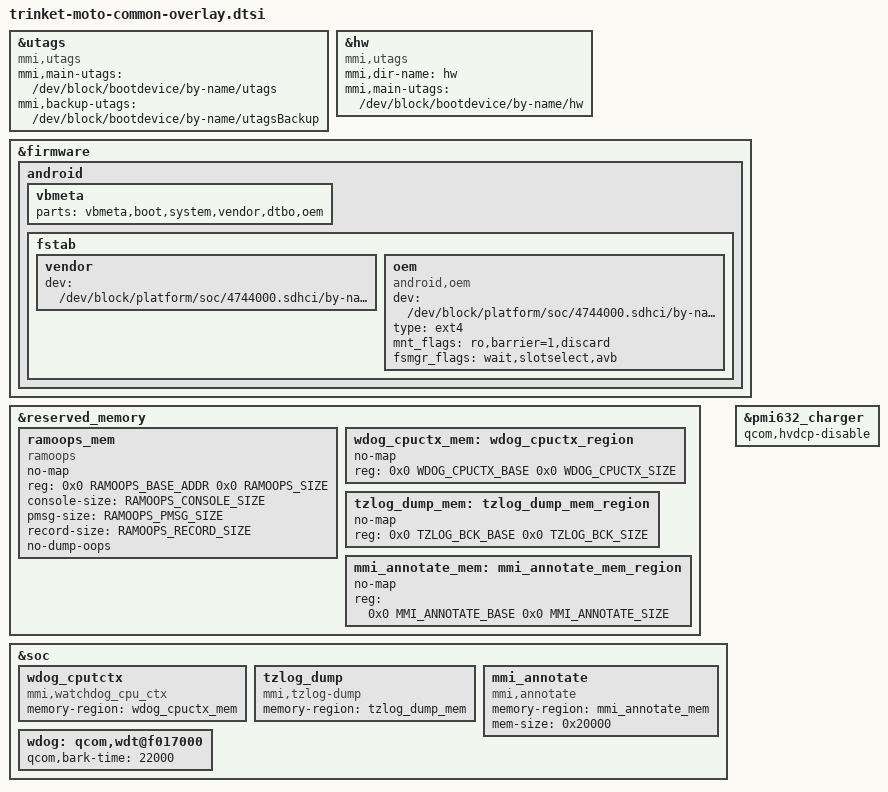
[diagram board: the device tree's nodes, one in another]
/* Copyright (c) 2018, The Linux Foundation. All rights reserved.
 *
 * This program is free software; you can redistribute it and/or modify
 * it under the terms of the GNU General Public License version 2 and
 * only version 2 as published by the Free Software Foundation.
 *
 * This program is distributed in the hope that it will be useful,
 * but WITHOUT ANY WARRANTY; without even the implied warranty of
 * MERCHANTABILITY or FITNESS FOR A PARTICULAR PURPOSE.  See the
 * GNU General Public License for more details.
 */

#include "trinket-qrd.dtsi"
#include <dt-bindings/moto/moto-mem-reserve.h>

&utags {
	compatible = "mmi,utags";
	mmi,main-utags = "/dev/block/bootdevice/by-name/utags";
	mmi,backup-utags = "/dev/block/bootdevice/by-name/utagsBackup";
};

&hw {
	compatible = "mmi,utags";
	mmi,dir-name = "hw";
	mmi,main-utags = "/dev/block/bootdevice/by-name/hw";
};


&firmware {
       android {
               vbmeta {
                       parts = "vbmeta,boot,system,vendor,dtbo,oem";
               };
               fstab {
                       vendor {
                               dev = "/dev/block/platform/soc/4744000.sdhci/by-name/vendor";
                       };
                       oem {
                               compatible = "android,oem";
                               dev = "/dev/block/platform/soc/4744000.sdhci/by-name/oem";
                               type = "ext4";
                               mnt_flags = "ro,barrier=1,discard";
                               fsmgr_flags = "wait,slotselect,avb";
                       };
               };
       };
};

&reserved_memory {
	ramoops_mem {
		compatible = "ramoops";
		no-map;
		reg = <0x0 RAMOOPS_BASE_ADDR 0x0 RAMOOPS_SIZE>;
		console-size = <RAMOOPS_CONSOLE_SIZE>;
		pmsg-size = <RAMOOPS_PMSG_SIZE>;
		record-size = <RAMOOPS_RECORD_SIZE>;
		no-dump-oops;
	};

	wdog_cpuctx_mem: wdog_cpuctx_region {
		no-map;
		reg = <0x0 WDOG_CPUCTX_BASE
				0x0 WDOG_CPUCTX_SIZE>;
	};

	tzlog_dump_mem: tzlog_dump_mem_region {
		no-map;
		reg = <0x0  TZLOG_BCK_BASE
				0x0 TZLOG_BCK_SIZE>;
	};

	mmi_annotate_mem: mmi_annotate_mem_region {
		no-map;
		reg = <0x0  MMI_ANNOTATE_BASE
				0x0 MMI_ANNOTATE_SIZE>;
	};

};

&soc {
	wdog_cputctx {
		compatible = "mmi,watchdog_cpu_ctx";
		memory-region = <&wdog_cpuctx_mem>;
	};

	tzlog_dump {
		compatible = "mmi,tzlog-dump";
		memory-region = <&tzlog_dump_mem>;
	};

	mmi_annotate {
		compatible = "mmi,annotate";
		memory-region = <&mmi_annotate_mem>;
		mem-size = <0x20000>;
	};

	wdog: qcom,wdt@f017000 {
		qcom,bark-time = <22000>;
	};
};

&pmi632_charger {
	qcom,hvdcp-disable;
};

